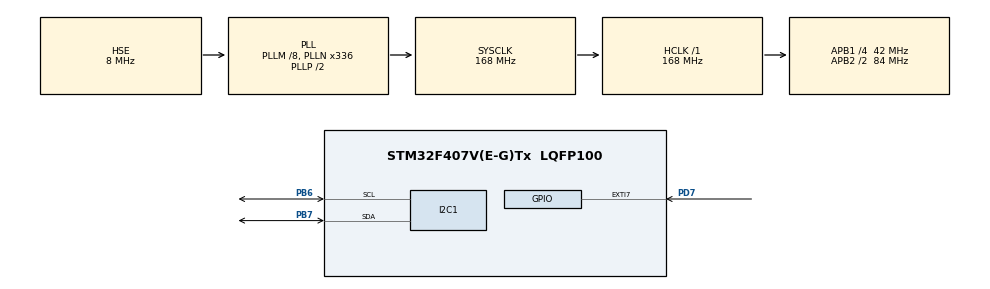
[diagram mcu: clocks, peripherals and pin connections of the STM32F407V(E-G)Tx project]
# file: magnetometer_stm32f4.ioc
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FREERTOS.Tasks01=lis3mdl_task,0,128,LIS3MDLTask,Default,NULL,Dynamic,NULL,NULL
I2C1.I2C_Mode=I2C_Fast
Mcu.Family=STM32F4
Mcu.Name=STM32F407V(E-G)Tx
Mcu.Package=LQFP100
NVIC.EXTI9_5_IRQn=true\:0\:0\:false\:false\:true\:false\:true\:true
NVIC.I2C1_ER_IRQn=true\:5\:0\:false\:false\:true\:true\:true\:true
NVIC.I2C1_EV_IRQn=true\:5\:0\:false\:false\:true\:true\:true\:true
NVIC.PriorityGroup=NVIC_PRIORITYGROUP_4
NVIC.TIM1_UP_TIM10_IRQn=true\:0\:0\:false\:false\:true\:false\:false\:true
NVIC.TimeBase=TIM1_UP_TIM10_IRQn
NVIC.TimeBaseIP=TIM1
PB6.Mode=I2C
PB6.Signal=I2C1_SCL
PB7.Mode=I2C
PB7.Signal=I2C1_SDA
PC14-OSC32_IN.Mode=LSE-External-Oscillator
PC14-OSC32_IN.Signal=RCC_OSC32_IN
PC15-OSC32_OUT.Mode=LSE-External-Oscillator
PC15-OSC32_OUT.Signal=RCC_OSC32_OUT
PD7.Signal=GPXTI7
PH0-OSC_IN.Mode=HSE-External-Oscillator
PH0-OSC_IN.Signal=RCC_OSC_IN
PH1-OSC_OUT.Mode=HSE-External-Oscillator
PH1-OSC_OUT.Signal=RCC_OSC_OUT
ProjectManager.HeapSize=0x200
ProjectManager.StackSize=0x400
ProjectManager.TargetToolchain=Makefile
RCC.48MHZClocksFreq_Value=84000000
RCC.AHBFreq_Value=168000000
RCC.APB1CLKDivider=RCC_HCLK_DIV4
RCC.APB1Freq_Value=42000000
RCC.APB1TimFreq_Value=84000000
RCC.APB2CLKDivider=RCC_HCLK_DIV2
RCC.APB2Freq_Value=84000000
RCC.APB2TimFreq_Value=168000000
RCC.CortexFreq_Value=168000000
RCC.HCLKFreq_Value=168000000
RCC.HSE_VALUE=8000000
RCC.HSI_VALUE=16000000
RCC.PLLM=8
RCC.PLLN=336
RCC.PLLSourceVirtual=RCC_PLLSOURCE_HSE
RCC.SYSCLKFreq_VALUE=168000000
RCC.SYSCLKSource=RCC_SYSCLKSOURCE_PLLCLK
RCC.VCOOutputFreq_Value=336000000
VP_FREERTOS_VS_CMSIS_V1.Mode=CMSIS_V1
VP_SYS_VS_tim1.Mode=TIM1
board=custom

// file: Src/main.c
/* USER CODE BEGIN Header */
/**
  ******************************************************************************
  * @file           : main.c
  * @brief          : Main program body
  ******************************************************************************
  * @attention
  *
  * <h2><center>&copy; Copyright (c) 2019 STMicroelectronics.
  * Copyright (c) 2019, Pablo Maiolo.
  * All rights reserved.</center></h2>
  *
  * This software component is licensed by ST under Ultimate Liberty license
  * SLA0044, the "License"; You may not use this file except in compliance with
  * the License. You may obtain a copy of the License at:
  *                             www.st.com/SLA0044
  *
  ******************************************************************************
  */
/* USER CODE END Header */

#include "main.h"
#include "cmsis_os.h"

/* USER CODE BEGIN Includes */
#include "lis3mdl/lis3mdl.h"
/* USER CODE END Includes */

/* USER CODE BEGIN PTD */
struct magnetometer_data
{
	float magnetic_field[3];
	float temperature;
};
/* USER CODE END PTD */

/* USER CODE BEGIN PD */
struct magnetometer_data magnetic_data;
/* USER CODE END PD */

I2C_HandleTypeDef hi2c1;

osThreadId lis3mdl_taskHandle;

void SystemClock_Config(void);
static void MX_GPIO_Init(void);
static void MX_I2C1_Init(void);
void LIS3MDLTask(void const * argument);

int main(void)
{

  /* MCU Configuration--------------------------------------------------------*/

  /* Reset of all peripherals, Initializes the Flash interface and the Systick. */
  HAL_Init();

  /* Configure the system clock */
  SystemClock_Config();

  /* Initialize all configured peripherals */
  MX_GPIO_Init();
  MX_I2C1_Init();

  /* Create the thread(s) */
  /* definition and creation of lis3mdl_task */
  osThreadDef(lis3mdl_task, LIS3MDLTask, osPriorityNormal, 0, 128);
  lis3mdl_taskHandle = osThreadCreate(osThread(lis3mdl_task), NULL);

  /* Start scheduler */
  osKernelStart();

  /* We should never get here as control is now taken by the scheduler */

  /* Infinite loop */
  while (1)
  {

  }
}

void SystemClock_Config(void)
{
  RCC_OscInitTypeDef RCC_OscInitStruct = {0};
  RCC_ClkInitTypeDef RCC_ClkInitStruct = {0};

  /** Configure the main internal regulator output voltage
  */
  __HAL_RCC_PWR_CLK_ENABLE();
  __HAL_PWR_VOLTAGESCALING_CONFIG(PWR_REGULATOR_VOLTAGE_SCALE1);
  /** Initializes the CPU, AHB and APB busses clocks
  */
  RCC_OscInitStruct.OscillatorType = RCC_OSCILLATORTYPE_HSE;
  RCC_OscInitStruct.HSEState = RCC_HSE_ON;
  RCC_OscInitStruct.PLL.PLLState = RCC_PLL_ON;
  RCC_OscInitStruct.PLL.PLLSource = RCC_PLLSOURCE_HSE;
  RCC_OscInitStruct.PLL.PLLM = 8;
  RCC_OscInitStruct.PLL.PLLN = 336;
  RCC_OscInitStruct.PLL.PLLP = RCC_PLLP_DIV2;
  RCC_OscInitStruct.PLL.PLLQ = 4;
  if (HAL_RCC_OscConfig(&RCC_OscInitStruct) != HAL_OK)
  {
    Error_Handler();
  }
  /** Initializes the CPU, AHB and APB busses clocks
  */
  RCC_ClkInitStruct.ClockType = RCC_CLOCKTYPE_HCLK|RCC_CLOCKTYPE_SYSCLK
                              |RCC_CLOCKTYPE_PCLK1|RCC_CLOCKTYPE_PCLK2;
  RCC_ClkInitStruct.SYSCLKSource = RCC_SYSCLKSOURCE_PLLCLK;
  RCC_ClkInitStruct.AHBCLKDivider = RCC_SYSCLK_DIV1;
  RCC_ClkInitStruct.APB1CLKDivider = RCC_HCLK_DIV4;
  RCC_ClkInitStruct.APB2CLKDivider = RCC_HCLK_DIV2;

  if (HAL_RCC_ClockConfig(&RCC_ClkInitStruct, FLASH_LATENCY_5) != HAL_OK)
  {
    Error_Handler();
  }
}

static void MX_I2C1_Init(void)
{

  hi2c1.Instance = I2C1;
  hi2c1.Init.ClockSpeed = 400000;
  hi2c1.Init.DutyCycle = I2C_DUTYCYCLE_2;
  hi2c1.Init.OwnAddress1 = 0;
  hi2c1.Init.AddressingMode = I2C_ADDRESSINGMODE_7BIT;
  hi2c1.Init.DualAddressMode = I2C_DUALADDRESS_DISABLE;
  hi2c1.Init.OwnAddress2 = 0;
  hi2c1.Init.GeneralCallMode = I2C_GENERALCALL_DISABLE;
  hi2c1.Init.NoStretchMode = I2C_NOSTRETCH_DISABLE;
  if (HAL_I2C_Init(&hi2c1) != HAL_OK)
  {
    Error_Handler();
  }

}

static void MX_GPIO_Init(void)
{
  GPIO_InitTypeDef GPIO_InitStruct = {0};

  /* GPIO Ports Clock Enable */
  __HAL_RCC_GPIOC_CLK_ENABLE();
  __HAL_RCC_GPIOH_CLK_ENABLE();
  __HAL_RCC_GPIOD_CLK_ENABLE();
  __HAL_RCC_GPIOB_CLK_ENABLE();

  /*Configure GPIO pin : PD7 */
  GPIO_InitStruct.Pin = GPIO_PIN_7;
  GPIO_InitStruct.Mode = GPIO_MODE_IT_RISING;
  GPIO_InitStruct.Pull = GPIO_NOPULL;
  HAL_GPIO_Init(GPIOD, &GPIO_InitStruct);

  /* EXTI interrupt init*/
  HAL_NVIC_SetPriority(EXTI9_5_IRQn, 0, 0);
  HAL_NVIC_EnableIRQ(EXTI9_5_IRQn);

}

void LIS3MDLTask(void const * argument)
{
	osEvent evt;
	struct lis3mdl_dev lis3mdl;

	/* USER CODE BEGIN 5 */
	lis3mdl_init(&lis3mdl, &hi2c1);
	lis3mdl_set_output_data_rate(&lis3mdl, OUTPUT_RATE_10);
	lis3mdl_set_axis_mode(&lis3mdl, AXIS_HIGH_PERF, AXIS_HIGH_PERF);
	lis3mdl_set_full_scale(&lis3mdl, FS_12GAUSS);
	lis3mdl_set_system_mode(&lis3mdl, SYS_MODE_CONTINUOUS_CONVERSION);

	/* Infinite loop */
	for(;;)
	{
		evt = osSignalWait(0x01, osWaitForever);
		if(evt.status == osEventSignal)
		{
			lis3mdl_read_mag_axis(&lis3mdl, magnetic_data.magnetic_field);
			lis3mdl_read_temp(&lis3mdl, &(magnetic_data.temperature));
		}
	}
	/* USER CODE END 5 */
}

void HAL_GPIO_EXTI_Callback(uint16_t GPIO_Pin)
{
	static int drdy_ticks = 0;

	if(GPIO_Pin == GPIO_PIN_7)
	{
		/* Count 10 ticks to get a 1 Hz reading rate from a 10 Hz update rate */
		drdy_ticks++;
		if(drdy_ticks == 10)
		{
			drdy_ticks = 0;
			osSignalSet(lis3mdl_taskHandle, 0x01);
		}
	}
}

void HAL_TIM_PeriodElapsedCallback(TIM_HandleTypeDef *htim)
{
  if (htim->Instance == TIM1) {
    HAL_IncTick();
  }
}

void Error_Handler(void)
{
}

/************************ (C) COPYRIGHT STMicroelectronics *****END OF FILE****/
